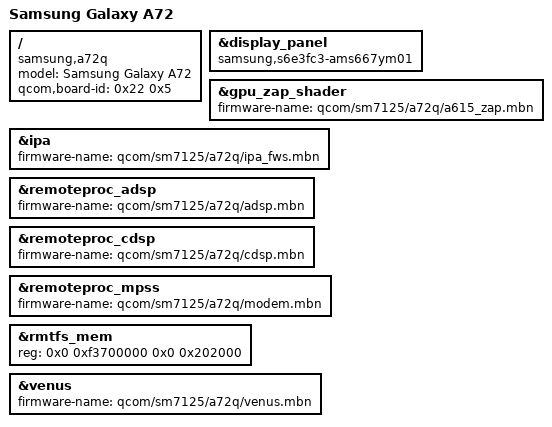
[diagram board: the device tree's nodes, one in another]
// SPDX-License-Identifier: GPL-2.0
/*
 * SM7125 Samsung Galaxy A72 (a72q) specific device tree source
 *
 * Copyright (c) 2026, Erikas Bitovtas. All rights reserved.
 */

/dts-v1/;

#include "sm7125-samsung-common.dtsi"

/ {
	model = "Samsung Galaxy A72";
	compatible = "samsung,a72q", "qcom,sm7125";
	qcom,board-id = <0x22 0x5>;
};

&display_panel {
	compatible = "samsung,s6e3fc3-ams667ym01", "samsung,s6e3fc3";

	status = "okay";
};

&gpu_zap_shader {
	firmware-name = "qcom/sm7125/a72q/a615_zap.mbn";
};

&ipa {
	firmware-name = "qcom/sm7125/a72q/ipa_fws.mbn";

	status = "okay";
};

&remoteproc_adsp {
	firmware-name = "qcom/sm7125/a72q/adsp.mbn";

	status = "okay";
};

&remoteproc_cdsp {
	firmware-name = "qcom/sm7125/a72q/cdsp.mbn";

	status = "okay";
};

&remoteproc_mpss {
	firmware-name = "qcom/sm7125/a72q/modem.mbn";

	status = "okay";
};

&rmtfs_mem {
	reg = <0x0 0xf3700000 0x0 0x202000>;
};

&venus {
	firmware-name = "qcom/sm7125/a72q/venus.mbn";
};
